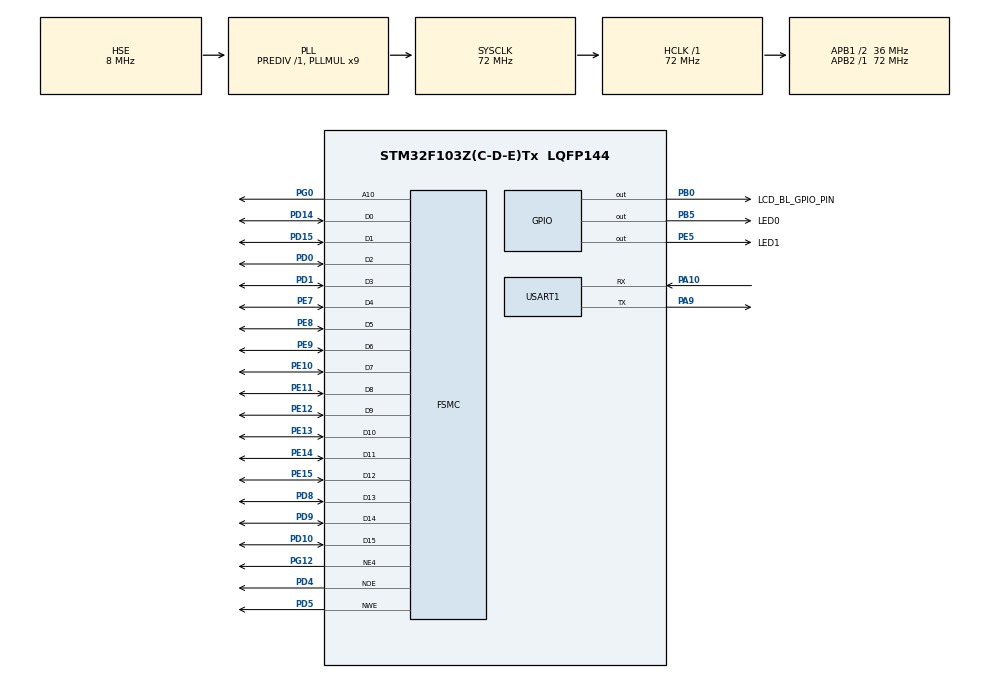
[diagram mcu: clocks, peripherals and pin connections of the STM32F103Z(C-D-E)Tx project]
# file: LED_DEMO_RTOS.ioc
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FREERTOS.Tasks01=sumupTask,24,128,StartSumupTask,Default,NULL,Dynamic,NULL,NULL;lvglTask,24,1024,StartlvglTask,Default,NULL,Dynamic,NULL,NULL
FREERTOS.configCHECK_FOR_STACK_OVERFLOW=2
FREERTOS.configTOTAL_HEAP_SIZE=20480
FREERTOS.configUSE_MALLOC_FAILED_HOOK=1
FSMC.AddressSetupTime4=0
FSMC.BusTurnAroundDuration4=0
FSMC.DataSetupTime4=15
FSMC.ExtendedAddressSetupTime4=0
FSMC.ExtendedBusTurnAroundDuration4=0
FSMC.ExtendedDataSetupTime4=1
FSMC.ExtendedMode4=FSMC_EXTENDED_MODE_ENABLE
Mcu.Family=STM32F1
Mcu.Name=STM32F103Z(C-D-E)Tx
Mcu.Package=LQFP144
NVIC.PriorityGroup=NVIC_PRIORITYGROUP_4
NVIC.TIM3_IRQn=true\:5\:0\:true\:false\:true\:true\:true\:true\:true
NVIC.TIM5_IRQn=true\:6\:0\:true\:false\:true\:true\:true\:true\:true
NVIC.TIM6_IRQn=true\:15\:0\:false\:false\:true\:false\:false\:true\:true
NVIC.TimeBase=TIM6_IRQn
NVIC.TimeBaseIP=TIM6
OSC_IN.Mode=HSE-External-Oscillator
OSC_IN.Signal=RCC_OSC_IN
OSC_OUT.Mode=HSE-External-Oscillator
OSC_OUT.Signal=RCC_OSC_OUT
PA10.Mode=Asynchronous
PA10.Signal=USART1_RX
PA13.Mode=Serial_Wire
PA13.Signal=SYS_JTMS-SWDIO
PA14.Mode=Serial_Wire
PA14.Signal=SYS_JTCK-SWCLK
PA9.Mode=Asynchronous
PA9.Signal=USART1_TX
PB0.GPIO_Label=LCD_BL_GPIO_PIN
PB0.GPIO_Speed=GPIO_SPEED_FREQ_HIGH
PB0.PinState=GPIO_PIN_SET
PB0.Signal=GPIO_Output
PB5.GPIO_Label=LED0
PB5.PinState=GPIO_PIN_SET
PB5.Signal=GPIO_Output
PC14-OSC32_IN.Mode=LSE-External-Oscillator
PC14-OSC32_IN.Signal=RCC_OSC32_IN
PC15-OSC32_OUT.Mode=LSE-External-Oscillator
PC15-OSC32_OUT.Signal=RCC_OSC32_OUT
PD0.Signal=FSMC_D2_DA2
PD1.Signal=FSMC_D3_DA3
PD10.Signal=FSMC_D15_DA15
PD14.Signal=FSMC_D0_DA0
PD15.Signal=FSMC_D1_DA1
PD4.Signal=FSMC_NOE
PD5.Signal=FSMC_NWE
PD8.Signal=FSMC_D13_DA13
PD9.Signal=FSMC_D14_DA14
PE10.Signal=FSMC_D7_DA7
PE11.Signal=FSMC_D8_DA8
PE12.Signal=FSMC_D9_DA9
PE13.Signal=FSMC_D10_DA10
PE14.Signal=FSMC_D11_DA11
PE15.Signal=FSMC_D12_DA12
PE5.GPIO_Label=LED1
PE5.PinState=GPIO_PIN_SET
PE5.Signal=GPIO_Output
PE7.Signal=FSMC_D4_DA4
PE8.Signal=FSMC_D5_DA5
PE9.Signal=FSMC_D6_DA6
PG0.Signal=FSMC_A10
PG12.Mode=NorPsramChipSelect4_4
PG12.Signal=FSMC_NE4
ProjectManager.HeapSize=0x200
ProjectManager.StackSize=0x400
ProjectManager.TargetToolchain=Makefile
RCC.AHBFreq_Value=72000000
RCC.APB1CLKDivider=RCC_HCLK_DIV2
RCC.APB1Freq_Value=36000000
RCC.APB1TimFreq_Value=72000000
RCC.APB2Freq_Value=72000000
RCC.APB2TimFreq_Value=72000000
RCC.HCLKFreq_Value=72000000
RCC.PLLMUL=RCC_PLL_MUL9
RCC.PLLSourceVirtual=RCC_PLLSOURCE_HSE
RCC.SYSCLKFreq_VALUE=72000000
RCC.SYSCLKSource=RCC_SYSCLKSOURCE_PLLCLK
RCC.USBFreq_Value=72000000
SH.FSMC_A10.0=FSMC_A10,A10_4
SH.FSMC_D0_DA0.0=FSMC_D0,16b-d4
SH.FSMC_D10_DA10.0=FSMC_D10,16b-d4
SH.FSMC_D11_DA11.0=FSMC_D11,16b-d4
SH.FSMC_D12_DA12.0=FSMC_D12,16b-d4
SH.FSMC_D13_DA13.0=FSMC_D13,16b-d4
SH.FSMC_D14_DA14.0=FSMC_D14,16b-d4
SH.FSMC_D15_DA15.0=FSMC_D15,16b-d4
SH.FSMC_D1_DA1.0=FSMC_D1,16b-d4
SH.FSMC_D2_DA2.0=FSMC_D2,16b-d4
SH.FSMC_D3_DA3.0=FSMC_D3,16b-d4
SH.FSMC_D4_DA4.0=FSMC_D4,16b-d4
SH.FSMC_D5_DA5.0=FSMC_D5,16b-d4
SH.FSMC_D6_DA6.0=FSMC_D6,16b-d4
SH.FSMC_D7_DA7.0=FSMC_D7,16b-d4
SH.FSMC_D8_DA8.0=FSMC_D8,16b-d4
SH.FSMC_D9_DA9.0=FSMC_D9,16b-d4
SH.FSMC_NOE.0=FSMC_NOE,Lcd4
SH.FSMC_NWE.0=FSMC_NWE,Lcd4
TIM3.Period=9999
TIM3.Prescaler=7199
TIM5.Period=4999
TIM5.Prescaler=7199
USART1.VirtualMode=VM_ASYNC
VP_FREERTOS_VS_CMSIS_V2.Mode=CMSIS_V2
VP_SYS_VS_tim6.Mode=TIM6
VP_TIM3_VS_ClockSourceINT.Mode=Internal
VP_TIM5_VS_ClockSourceINT.Mode=Internal
board=custom

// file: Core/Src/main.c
/* USER CODE BEGIN Header */
/**
  ******************************************************************************
  * @file           : main.c
  * @brief          : Main program body
  ******************************************************************************
  * @attention
  *
  * Copyright (c) 2026 STMicroelectronics.
  * All rights reserved.
  *
  * This software is licensed under terms that can be found in the LICENSE file
  * in the root directory of this software component.
  * If no LICENSE file comes with this software, it is provided AS-IS.
  *
  ******************************************************************************
  */
/* USER CODE END Header */
#include "main.h"
#include "cmsis_os.h"
#include "tim.h"
#include "usart.h"
#include "gpio.h"
#include "fsmc.h"

/* USER CODE BEGIN Includes */
#include <stdio.h>

#include "interrupt_demo.h"
#include "lcd.h"

/* USER CODE END Includes */

void SystemClock_Config(void);
void MX_FREERTOS_Init(void);

int main(void)
{

  /* MCU Configuration--------------------------------------------------------*/

  /* Reset of all peripherals, Initializes the Flash interface and the Systick. */
  HAL_Init();

  /* Configure the system clock */
  SystemClock_Config();

  /* Initialize all configured peripherals */
  MX_GPIO_Init();
  MX_TIM3_Init();
  MX_TIM5_Init();
  MX_USART1_UART_Init();
  MX_FSMC_Init();
  /* USER CODE BEGIN 2 */
  lcd_init();
  lcd_display_dir(1U);

  printf("LCD init done, ID: %04lX\r\n", (unsigned long)lcddev.id);
  printf("LCD size: %u x %u\r\n", lcddev.width, lcddev.height);

  /* USER CODE END 2 */

  /* Init scheduler */
  osKernelInitialize();  /* Call init function for freertos objects (in cmsis_os2.c) */
  MX_FREERTOS_Init();

  /* Start scheduler */
  osKernelStart();

  /* We should never get here as control is now taken by the scheduler */

  /* Infinite loop */
  while (1)
  {

  }
}

void SystemClock_Config(void)
{
  RCC_OscInitTypeDef RCC_OscInitStruct = {0};
  RCC_ClkInitTypeDef RCC_ClkInitStruct = {0};

  /** Initializes the RCC Oscillators according to the specified parameters
  * in the RCC_OscInitTypeDef structure.
  */
  RCC_OscInitStruct.OscillatorType = RCC_OSCILLATORTYPE_HSE;
  RCC_OscInitStruct.HSEState = RCC_HSE_ON;
  RCC_OscInitStruct.HSEPredivValue = RCC_HSE_PREDIV_DIV1;
  RCC_OscInitStruct.HSIState = RCC_HSI_ON;
  RCC_OscInitStruct.PLL.PLLState = RCC_PLL_ON;
  RCC_OscInitStruct.PLL.PLLSource = RCC_PLLSOURCE_HSE;
  RCC_OscInitStruct.PLL.PLLMUL = RCC_PLL_MUL9;
  if (HAL_RCC_OscConfig(&RCC_OscInitStruct) != HAL_OK)
  {
    Error_Handler();
  }

  /** Initializes the CPU, AHB and APB buses clocks
  */
  RCC_ClkInitStruct.ClockType = RCC_CLOCKTYPE_HCLK|RCC_CLOCKTYPE_SYSCLK
                              |RCC_CLOCKTYPE_PCLK1|RCC_CLOCKTYPE_PCLK2;
  RCC_ClkInitStruct.SYSCLKSource = RCC_SYSCLKSOURCE_PLLCLK;
  RCC_ClkInitStruct.AHBCLKDivider = RCC_SYSCLK_DIV1;
  RCC_ClkInitStruct.APB1CLKDivider = RCC_HCLK_DIV2;
  RCC_ClkInitStruct.APB2CLKDivider = RCC_HCLK_DIV1;

  if (HAL_RCC_ClockConfig(&RCC_ClkInitStruct, FLASH_LATENCY_2) != HAL_OK)
  {
    Error_Handler();
  }
}

void HAL_TIM_PeriodElapsedCallback(TIM_HandleTypeDef *htim)
{
  if (htim->Instance == TIM6)
  {
    HAL_IncTick();
  }
  /* USER CODE BEGIN Callback 1 */
  interrupt_demo_tim_period_elapsed_callback(htim);
  /* USER CODE END Callback 1 */
}

void Error_Handler(void)
{
  __disable_irq();
  while (1)
  {
  }
}

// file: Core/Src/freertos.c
/* USER CODE BEGIN Header */
/**
  ******************************************************************************
  * File Name          : freertos.c
  * Description        : Code for freertos applications
  ******************************************************************************
  * @attention
  *
  * Copyright (c) 2026 STMicroelectronics.
  * All rights reserved.
  *
  * This software is licensed under terms that can be found in the LICENSE file
  * in the root directory of this software component.
  * If no LICENSE file comes with this software, it is provided AS-IS.
  *
  ******************************************************************************
  */
/* USER CODE END Header */

#include "FreeRTOS.h"
#include "task.h"
#include "main.h"
#include "cmsis_os.h"

/* USER CODE BEGIN Includes */
#include "interrupt_demo.h"
#include "lvgl_demo.h"
#include "tim.h"
#include "delay.h"
/* USER CODE END Includes */

/* Definitions for sumupTask */
osThreadId_t sumupTaskHandle;
const osThreadAttr_t sumupTask_attributes = {
  .name = "sumupTask",
  .stack_size = 128 * 4,
  .priority = (osPriority_t) osPriorityNormal,
};
/* Definitions for lvglTask */
osThreadId_t lvglTaskHandle;
const osThreadAttr_t lvglTask_attributes = {
  .name = "lvglTask",
  .stack_size = 1024 * 4,
  .priority = (osPriority_t) osPriorityNormal,
};

void StartSumupTask(void *argument);
void StartlvglTask(void *argument);

void MX_FREERTOS_Init(void); /* (MISRA C 2004 rule 8.1) */

/* Hook prototypes */
void vApplicationStackOverflowHook(xTaskHandle xTask, signed char *pcTaskName);
void vApplicationMallocFailedHook(void);

/* USER CODE BEGIN 4 */
void vApplicationStackOverflowHook(xTaskHandle xTask, signed char *pcTaskName)
{
   /* Run time stack overflow checking is performed if
   configCHECK_FOR_STACK_OVERFLOW is defined to 1 or 2. This hook function is
   called if a stack overflow is detected. */
}
/* USER CODE END 4 */

/* USER CODE BEGIN 5 */
void vApplicationMallocFailedHook(void)
{
   /* vApplicationMallocFailedHook() will only be called if
   configUSE_MALLOC_FAILED_HOOK is set to 1 in FreeRTOSConfig.h. It is a hook
   function that will get called if a call to pvPortMalloc() fails.
   pvPortMalloc() is called internally by the kernel whenever a task, queue,
   timer or semaphore is created. It is also called by various parts of the
   demo application. If heap_1.c or heap_2.c are used, then the size of the
   heap available to pvPortMalloc() is defined by configTOTAL_HEAP_SIZE in
   FreeRTOSConfig.h, and the xPortGetFreeHeapSize() API function can be used
   to query the size of free heap space that remains (although it does not
   provide information on how the remaining heap might be fragmented). */
}
/* USER CODE END 5 */

void MX_FREERTOS_Init(void) {

  /* Create the thread(s) */
  /* creation of sumupTask */
  sumupTaskHandle = osThreadNew(StartSumupTask, NULL, &sumupTask_attributes);

  /* creation of lvglTask */
  lvglTaskHandle = osThreadNew(StartlvglTask, NULL, &lvglTask_attributes);

}

void StartSumupTask(void *argument)
{
  /* USER CODE BEGIN StartSumupTask */
  /* Infinite loop */
  interrupt_demo_task(argument);
  /* USER CODE END StartSumupTask */
}

void StartlvglTask(void *argument)
{
  /* USER CODE BEGIN StartlvglTask */
  /* Infinite loop */
  lvgl_demo_task(argument);
  /* USER CODE END StartlvglTask */
}
